# LPC178x7x register map
File version: 0.9-mod
CPU: CM3 r0p0, little endian, no MPU, no FPU, 3 interrupt priority bits
Registers are 32-bit, read-write, reset 0x0 unless marked. A register's access mark holds for its fields unless they carry their own. Offsets are from the block's base; [hi:lo] are bit positions; {n}, {i} and the like mark numbered series.

## GPIO — General Purpose I/O
Base 0x20098000
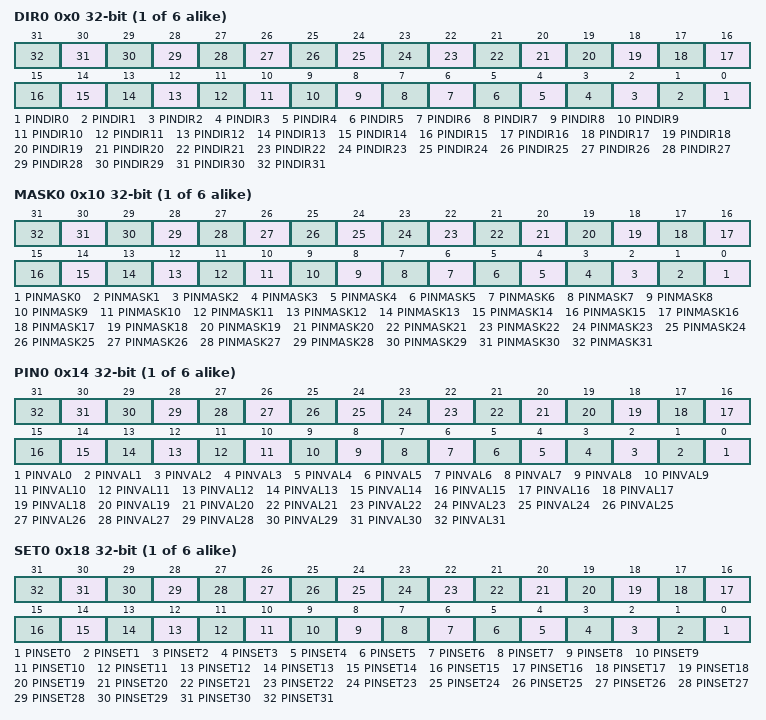
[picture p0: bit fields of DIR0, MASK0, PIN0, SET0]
{0x0+0x20*i} DIR{i} (i=0..5) — GPIO PortX Direction control register.
  [n] PINDIR{n} (n=0..31) — Fast GPIO Direction PORTx control bits. Bit 0 in DIRx controls pin Px[0], bit 31 in DIRx controls pin Px[31]. 0 = Controlled pin is input. 1 = Controlled pin is output.
{0x10+0x20*i} MASK{i} (i=0..5) — Mask register for PortX.
  [n] PINMASK{n} (n=0..31) — Fast GPIO physical pin access control. 0 = Controlled pin is affected by writes to the port's SETx, CLRx, and PINx register(s). Current state of the pin can be read from the PINx register. 1 = Controlled pin is not affected by writes into the port's SETx, CLRx and PINx register(s). When the PINx register is read, this bit will not be updated with the state of the physical pin.
{0x14+0x20*i} PIN{i} (i=0..5) — PortX Pin value register using FIOMASK.
  [n] PINVAL{n} (n=0..31) — Fast GPIO output value Set bits. Bit 0 in PINx corresponds to pin Px[0], bit 31 in PINx corresponds to pin Px[31]. 0 = Controlled pin output is set to LOW. 1 = Controlled pin output is set to HIGH.
{0x18+0x20*i} SET{i} (i=0..5) — PortX Output Set register using FIOMASK.
  [n] PINSET{n} (n=0..31) — Fast GPIO output value Set bits. Bit 0 in SETx controls pin Px[0], bit 31 in SETx controls pin Px[31]. 0 = Controlled pin output is unchanged. 1 = Controlled pin output is set to HIGH.
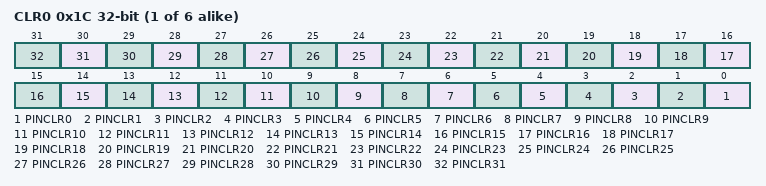
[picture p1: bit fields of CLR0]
{0x1C+0x20*i} CLR{i} (i=0..5) wo — PortX Output Clear register using FIOMASK.
  [n] PINCLR{n} (n=0..31) — Fast GPIO output value Clear bits. Bit 0 in CLRx controls pin Px[0], bit 31 in CLRx controls pin Px[31]. 0 = Controlled pin output is unchanged. 1 = Controlled pin output is set to LOW.

## WWDT — Windowed Watchdog Timer (WWDT)
Base 0x40000000
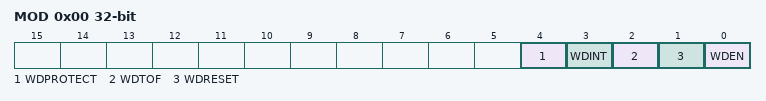
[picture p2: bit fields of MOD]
0x00 MOD — Watchdog mode register. This register determines the basic mode and status of the Watchdog Timer.
  [4] WDPROTECT — Watchdog update mode. This bit is Set Only. See Section WDPROTECT.
    0=CHANGE (The watchdog reload value (WDTC) can be changed at any time.); 1=CHANGE_W_CNT (The watchdog reload value (WDTC) can be changed only after the counter is below the value of WDWARNINT and WDWINDOW. Note: this mode is intended for use only when WDRESET =1.)
  [3] WDINT — Watchdog interrupt flag. Set when the timer reaches the value in WDWARNINT. Cleared by software. See Section WDINT.
  [2] WDTOF — Watchdog time-out flag. Set when the watchdog timer times out, by a feed error, or by events associated with WDPROTECT, cleared by software. Causes a chip reset if WDRESET = 1. See Section WDTOF.
  [1] WDRESET — Watchdog reset enable bit. This bit is Set Only. See Table 652.
    0=NO_RESET (A watchdog timeout will not cause a chip reset.); 1=RESET (A watchdog timeout will cause a chip reset.)
  [0] WDEN — Watchdog enable bit. This bit is Set Only. See Table 652.
    0=STOPPED (The watchdog timer is stopped.); 1=STARTED (The watchdog timer is running.)
0x04 TC reset 0xFF — Watchdog timer constant register. The value in this register determines the time-out value.
  [23:0] Count — Watchdog time-out interval.
0x08 FEED wo reset not defined — Watchdog feed sequence register. Writing 0xAA followed by 0x55 to this register reloads the Watchdog timer with the value contained in WDTC.
  [7:0] Feed — Feed value should be 0xAA followed by 0x55.
0x0C TV ro reset 0xFF — Watchdog timer value register. This register reads out the current value of the Watchdog timer.
  [23:0] Count — Counter timer value.
0x14 WARNINT — Watchdog Warning Interrupt compare value.
  [9:0] WARNINT — Watchdog warning interrupt compare value.
0x18 WINDOW reset 0xFFFFFF — Watchdog Window compare value.
  [23:0] WINDOW — Watchdog window value.
